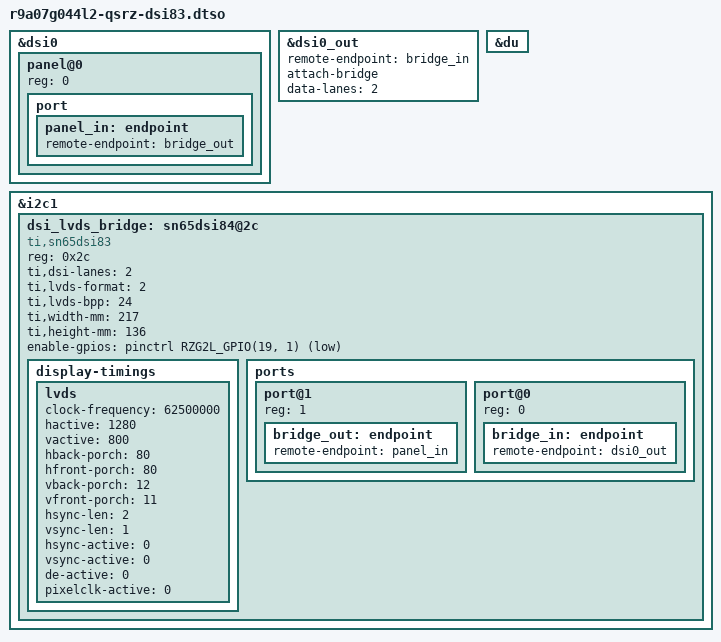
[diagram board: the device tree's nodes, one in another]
// SPDX-License-Identifier: (GPL-2.0 OR BSD-3-Clause)
/*
 * Copyright (C) 2023 Markus Bauer <MB@karo-electronics.com>
 */
/dts-v1/;
/plugin/;

#include <dt-bindings/gpio/gpio.h>
#include <dt-bindings/pinctrl/rzg2l-pinctrl.h>

&dsi0 {
	#address-cells = <1>;
	#size-cells = <0>;
	status = "okay";

	panel@0 {
		reg = <0>;
		status = "okay";

		port {
			panel_in: endpoint {
				remote-endpoint = <&bridge_out>;
			};
		};
	};
};

&dsi0_out {
	remote-endpoint = <&bridge_in>;
	attach-bridge;
	data-lanes = <2>;
};

&du {
	status = "okay";
};

&i2c1 {
	dsi_lvds_bridge: sn65dsi84@2c {
		compatible = "ti,sn65dsi83";
		reg = <0x2c>;
		ti,dsi-lanes = <2>;
		ti,lvds-format = <2>;
		ti,lvds-bpp = <24>;
		ti,width-mm = <217>;
		ti,height-mm = <136>;
		enable-gpios = <&pinctrl RZG2L_GPIO(19, 1) GPIO_ACTIVE_LOW>;
		status = "okay";

		display-timings {
			lvds {
				clock-frequency = <62500000>;
				hactive = <1280>;
				vactive = <800>;
				hback-porch = <80>;
				hfront-porch = <80>;
				vback-porch = <12>;
				vfront-porch = <11>;
				hsync-len = <2>;
				vsync-len = <1>;
				hsync-active = <0>;
				vsync-active = <0>;
				de-active = <0>;
				pixelclk-active = <0>;
			};
		};

		ports {
			#address-cells = <1>;
			#size-cells = <0>;

			port@1 {
				reg = <1>;

				bridge_out: endpoint {
					remote-endpoint = <&panel_in>;
				};
			};

			port@0 {
				reg = <0>;

				bridge_in: endpoint {
					remote-endpoint = <&dsi0_out>;
				};
			};
		};
	};
};
